# STM32H723 register map
File version: 2.2
CPU: CM7 r0p1, little endian, MPU, FPU, 4 interrupt priority bits
Registers are 32-bit, read-write, reset 0x0 unless marked. A register's access mark holds for its fields unless they carry their own. Offsets are from the block's base; [hi:lo] are bit positions.

## ADC12_Common — Analog-to-Digital Converter
Base 0x40022300
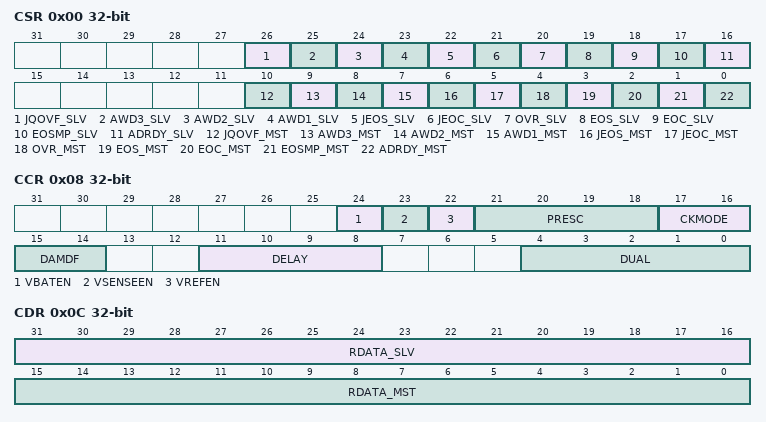
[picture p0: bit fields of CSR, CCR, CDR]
0x00 CSR ro — ADC Common status register
  [26] JQOVF_SLV — Injected Context Queue Overflow flag of the slave ADC
  [25] AWD3_SLV — Analog watchdog 3 flag of the slave ADC
  [24] AWD2_SLV — Analog watchdog 2 flag of the slave ADC
  [23] AWD1_SLV — Analog watchdog 1 flag of the slave ADC
  [22] JEOS_SLV — End of injected sequence flag of the slave ADC
  [21] JEOC_SLV — End of injected conversion flag of the slave ADC
  [20] OVR_SLV — Overrun flag of the slave ADC
  [19] EOS_SLV — End of regular sequence flag of the slave ADC
  [18] EOC_SLV — End of regular conversion of the slave ADC
  [17] EOSMP_SLV — End of Sampling phase flag of the slave ADC
  [16] ADRDY_SLV — Slave ADC ready
  [10] JQOVF_MST — Injected Context Queue Overflow flag of the master ADC
  [9] AWD3_MST — Analog watchdog 3 flag of the master ADC
  [8] AWD2_MST — Analog watchdog 2 flag of the master ADC
  [7] AWD1_MST — Analog watchdog 1 flag of the master ADC
  [6] JEOS_MST — End of injected sequence flag of the master ADC
  [5] JEOC_MST — End of injected conversion flag of the master ADC
  [4] OVR_MST — Overrun flag of the master ADC
  [3] EOS_MST — End of regular sequence flag of the master ADC
  [2] EOC_MST — End of regular conversion of the master ADC
  [1] EOSMP_MST — End of Sampling phase flag of the master ADC
  [0] ADRDY_MST — Master ADC ready
0x08 CCR — ADC common control register
  [24] VBATEN — VBAT enable
  [23] VSENSEEN — Temperature sensor enable
  [22] VREFEN — VREFINT enable
  [21:18] PRESC — ADC prescaler
  [17:16] CKMODE — ADC clock mode
  [15:14] DAMDF — Dual ADC Mode Data Format
  [11:8] DELAY — Delay between 2 sampling phases
  [4:0] DUAL — Dual ADC mode selection
0x0C CDR ro — ADC common regular data register for dual and triple modes
  [31:16] RDATA_SLV — Regular data of the slave ADC
  [15:0] RDATA_MST — Regular data of the master ADC
0x10 CDR2 ro — ADC x common regular data register for 32-bit dual mode
  [31:0] RDATA_ALT — Regular data of the master/slave alternated ADCs

## CAN_CCU — CCU registers
Base 0x4000A800
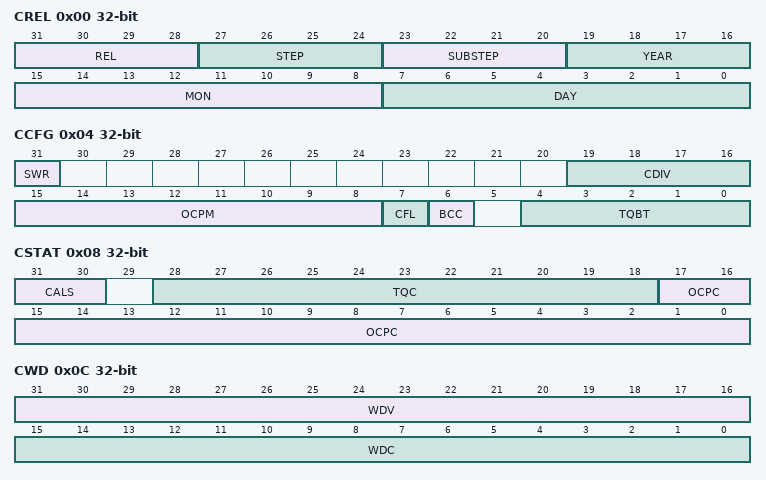
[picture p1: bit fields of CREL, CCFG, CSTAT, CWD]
0x00 CREL — Clock Calibration Unit Core Release Register
  [31:28] REL — Core Release
  [27:24] STEP — Step of Core Release
  [23:20] SUBSTEP — Sub-step of Core Release
  [19:16] YEAR — Time Stamp Year
  [15:8] MON — Time Stamp Month
  [7:0] DAY — Time Stamp Day
0x04 CCFG — Calibration Configuration Register
  [31] SWR — Software Reset
  [19:16] CDIV — Clock Divider
  [15:8] OCPM — Oscillator Clock Periods Minimum
  [7] CFL — Calibration Field Length
  [6] BCC — Bypass Clock Calibration
  [4:0] TQBT — Time Quanta per Bit Time
0x08 CSTAT — Calibration Status Register
  [31:30] CALS — Calibration State
  [28:18] TQC — Time Quanta Counter
  [17:0] OCPC — Oscillator Clock Period Counter
0x0C CWD — Calibration Watchdog Register
  [31:16] WDV, [15:0] WDC
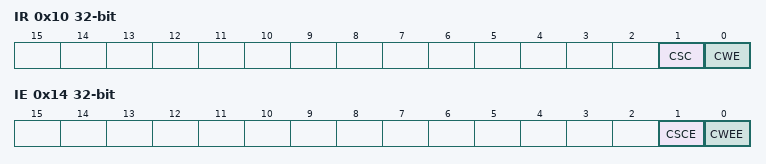
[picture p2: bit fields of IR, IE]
0x10 IR — Clock Calibration Unit Interrupt Register
  [1] CSC — Calibration State Changed
  [0] CWE — Calibration Watchdog Event
0x14 IE — Clock Calibration Unit Interrupt Enable Register
  [1] CSCE — Calibration State Changed Enable
  [0] CWEE — Calibration Watchdog Event Enable

## COMP1
Base 0x58003800
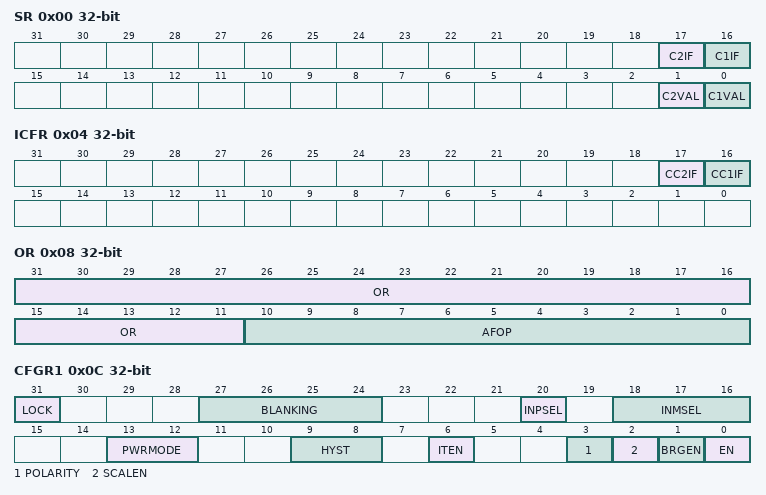
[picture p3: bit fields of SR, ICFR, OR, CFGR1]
0x00 SR ro — Comparator status register
  [17] C2IF — COMP channel 2 Interrupt Flag
  [16] C1IF — COMP channel 1 Interrupt Flag
  [1] C2VAL — COMP channel 2 output status bit
  [0] C1VAL — COMP channel 1 output status bit
0x04 ICFR wo — Comparator interrupt clear flag register
  [17] CC2IF — Clear COMP channel 2 Interrupt Flag
  [16] CC1IF — Clear COMP channel 1 Interrupt Flag
0x08 OR — Comparator option register
  [31:11] OR — Option Register
  [10:0] AFOP — Selection of source for alternate function of output ports
0x0C CFGR1 — Comparator configuration register 1
  [31] LOCK — Lock bit
  [27:24] BLANKING — COMP channel 1 blanking source selection bits
  [20] INPSEL — COMP channel 1 non-inverting input selection bit
  [18:16] INMSEL — COMP channel 1 inverting input selection field
  [13:12] PWRMODE — Power Mode of the COMP channel 1
  [9:8] HYST — COMP channel 1 hysteresis selection bits
  [6] ITEN — COMP channel 1 interrupt enable
  [3] POLARITY — COMP channel 1 polarity selection bit
  [2] SCALEN — Voltage scaler enable bit
  [1] BRGEN — Scaler bridge enable
  [0] EN — COMP channel 1 enable bit
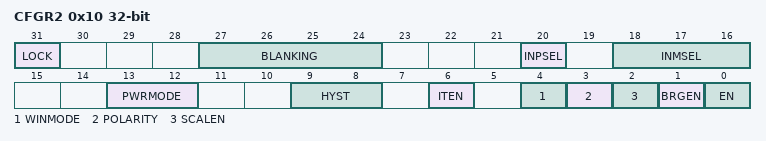
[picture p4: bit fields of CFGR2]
0x10 CFGR2 — Comparator configuration register 2
  [31] LOCK — Lock bit
  [27:24] BLANKING — COMP channel 1 blanking source selection bits
  [20] INPSEL — COMP channel 1 non-inverting input selection bit
  [18:16] INMSEL — COMP channel 1 inverting input selection field
  [13:12] PWRMODE — Power Mode of the COMP channel 1
  [9:8] HYST — COMP channel 1 hysteresis selection bits
  [6] ITEN — COMP channel 1 interrupt enable
  [4] WINMODE — Window comparator mode selection bit
  [3] POLARITY — COMP channel 1 polarity selection bit
  [2] SCALEN — Voltage scaler enable bit
  [1] BRGEN — Scaler bridge enable
  [0] EN — COMP channel 1 enable bit
